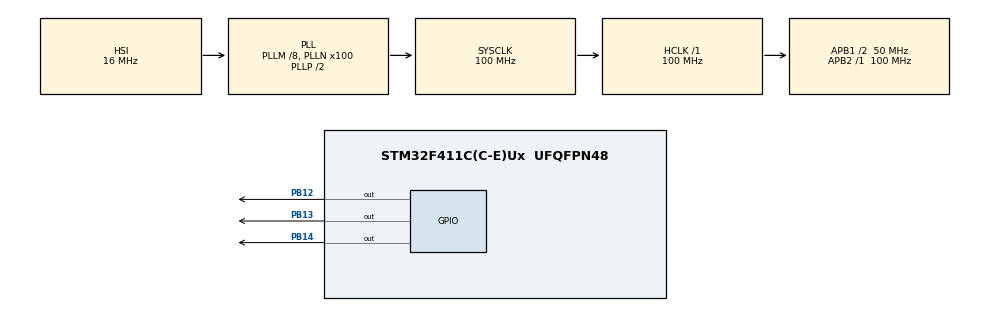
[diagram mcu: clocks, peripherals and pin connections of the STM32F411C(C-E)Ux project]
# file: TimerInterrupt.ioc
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Mcu.Family=STM32F4
Mcu.Name=STM32F411C(C-E)Ux
Mcu.Package=UFQFPN48
NVIC.PriorityGroup=NVIC_PRIORITYGROUP_4
NVIC.TIM2_IRQn=true\:0\:0\:false\:false\:true\:true\:true\:true
NVIC.TIM3_IRQn=true\:0\:0\:false\:false\:true\:true\:true\:true
NVIC.TIM4_IRQn=true\:0\:0\:false\:false\:true\:true\:true\:true
PA13.Mode=Serial_Wire
PA13.Signal=SYS_JTMS-SWDIO
PA14.Mode=Serial_Wire
PA14.Signal=SYS_JTCK-SWCLK
PB12.Signal=GPIO_Output
PB13.Signal=GPIO_Output
PB14.Signal=GPIO_Output
PH0\ -\ OSC_IN.Mode=HSE-External-Oscillator
PH0\ -\ OSC_IN.Signal=RCC_OSC_IN
PH1\ -\ OSC_OUT.Mode=HSE-External-Oscillator
PH1\ -\ OSC_OUT.Signal=RCC_OSC_OUT
ProjectManager.HeapSize=0x200
ProjectManager.StackSize=0x400
ProjectManager.TargetToolchain=STM32CubeIDE
RCC.48MHZClocksFreq_Value=50000000
RCC.AHBFreq_Value=100000000
RCC.APB1CLKDivider=RCC_HCLK_DIV2
RCC.APB1Freq_Value=50000000
RCC.APB1TimFreq_Value=100000000
RCC.APB2Freq_Value=100000000
RCC.APB2TimFreq_Value=100000000
RCC.CortexFreq_Value=100000000
RCC.HCLKFreq_Value=100000000
RCC.HSE_VALUE=25000000
RCC.HSI_VALUE=16000000
RCC.LSE_VALUE=32768
RCC.PLLM=8
RCC.PLLN=100
RCC.SYSCLKFreq_VALUE=100000000
RCC.SYSCLKSource=RCC_SYSCLKSOURCE_PLLCLK
RCC.VCOOutputFreq_Value=200000000
TIM2.Period=2000-1
TIM2.Prescaler=10000-1
TIM3.Period=5000-1
TIM3.Prescaler=10000-1
TIM4.Period=7500-1
TIM4.Prescaler=10000-1
VP_TIM2_VS_ClockSourceINT.Mode=Internal
VP_TIM3_VS_ClockSourceINT.Mode=Internal
VP_TIM4_VS_ClockSourceINT.Mode=Internal
board=custom

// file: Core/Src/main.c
/* USER CODE BEGIN Header */
/**
  ******************************************************************************
  * @file           : main.c
  * @brief          : Interrupción por Timer
  ******************************************************************************
  * Configuración:
  * - TIM2: Interrupción cada 200 ms (5Hz)
  * - TIM3: Interrupción cada 500 ms (2Hz)
  * - TIM4: Interrupción cada 750 ms (1.33Hz)
  ******************************************************************************
  */
/* USER CODE END Header */
#include "main.h"

TIM_HandleTypeDef htim2;
TIM_HandleTypeDef htim3;
TIM_HandleTypeDef htim4;

void SystemClock_Config(void);
static void MX_GPIO_Init(void);
static void MX_TIM2_Init(void);
static void MX_TIM3_Init(void);
static void MX_TIM4_Init(void);

int main(void)
{

  /* MCU Configuration--------------------------------------------------------*/

  /* Reset of all peripherals, Initializes the Flash interface and the Systick. */
  HAL_Init();

  /* Configure the system clock */
  SystemClock_Config();

  /* Initialize all configured peripherals */
  MX_GPIO_Init();
  MX_TIM2_Init();
  MX_TIM3_Init();
  MX_TIM4_Init();
  /* USER CODE BEGIN 2 */

  // Inicialización de timers en modo interrupción
  HAL_TIM_Base_Start_IT(&htim2);  // Inicia TIM2

  HAL_TIM_Base_Start_IT(&htim3);  // Inicia TIM3

  HAL_TIM_Base_Start_IT(&htim4);  // Inicia TIM4

  /* USER CODE END 2 */

  /* Infinite loop */
  while (1)
  {

  }
}

void SystemClock_Config(void)
{
  RCC_OscInitTypeDef RCC_OscInitStruct = {0};
  RCC_ClkInitTypeDef RCC_ClkInitStruct = {0};

  /** Configure the main internal regulator output voltage
  */
  __HAL_RCC_PWR_CLK_ENABLE();
  __HAL_PWR_VOLTAGESCALING_CONFIG(PWR_REGULATOR_VOLTAGE_SCALE1);

  /** Initializes the RCC Oscillators according to the specified parameters
  * in the RCC_OscInitTypeDef structure.
  */
  RCC_OscInitStruct.OscillatorType = RCC_OSCILLATORTYPE_HSI;
  RCC_OscInitStruct.HSIState = RCC_HSI_ON;
  RCC_OscInitStruct.HSICalibrationValue = RCC_HSICALIBRATION_DEFAULT;
  RCC_OscInitStruct.PLL.PLLState = RCC_PLL_ON;
  RCC_OscInitStruct.PLL.PLLSource = RCC_PLLSOURCE_HSI;
  RCC_OscInitStruct.PLL.PLLM = 8;
  RCC_OscInitStruct.PLL.PLLN = 100;
  RCC_OscInitStruct.PLL.PLLP = RCC_PLLP_DIV2;
  RCC_OscInitStruct.PLL.PLLQ = 4;
  if (HAL_RCC_OscConfig(&RCC_OscInitStruct) != HAL_OK)
  {
    Error_Handler();
  }

  /** Initializes the CPU, AHB and APB buses clocks
  */
  RCC_ClkInitStruct.ClockType = RCC_CLOCKTYPE_HCLK|RCC_CLOCKTYPE_SYSCLK
                              |RCC_CLOCKTYPE_PCLK1|RCC_CLOCKTYPE_PCLK2;
  RCC_ClkInitStruct.SYSCLKSource = RCC_SYSCLKSOURCE_PLLCLK;
  RCC_ClkInitStruct.AHBCLKDivider = RCC_SYSCLK_DIV1;
  RCC_ClkInitStruct.APB1CLKDivider = RCC_HCLK_DIV2;
  RCC_ClkInitStruct.APB2CLKDivider = RCC_HCLK_DIV1;

  if (HAL_RCC_ClockConfig(&RCC_ClkInitStruct, FLASH_LATENCY_3) != HAL_OK)
  {
    Error_Handler();
  }
}

static void MX_TIM2_Init(void)
{

  TIM_ClockConfigTypeDef sClockSourceConfig = {0};
  TIM_MasterConfigTypeDef sMasterConfig = {0};

  htim2.Instance = TIM2;
  htim2.Init.Prescaler = 10000-1;
  htim2.Init.CounterMode = TIM_COUNTERMODE_UP;
  htim2.Init.Period = 2000-1;
  htim2.Init.ClockDivision = TIM_CLOCKDIVISION_DIV1;
  htim2.Init.AutoReloadPreload = TIM_AUTORELOAD_PRELOAD_DISABLE;
  if (HAL_TIM_Base_Init(&htim2) != HAL_OK)
  {
    Error_Handler();
  }
  sClockSourceConfig.ClockSource = TIM_CLOCKSOURCE_INTERNAL;
  if (HAL_TIM_ConfigClockSource(&htim2, &sClockSourceConfig) != HAL_OK)
  {
    Error_Handler();
  }
  sMasterConfig.MasterOutputTrigger = TIM_TRGO_RESET;
  sMasterConfig.MasterSlaveMode = TIM_MASTERSLAVEMODE_DISABLE;
  if (HAL_TIMEx_MasterConfigSynchronization(&htim2, &sMasterConfig) != HAL_OK)
  {
    Error_Handler();
  }

}

static void MX_TIM3_Init(void)
{

  TIM_ClockConfigTypeDef sClockSourceConfig = {0};
  TIM_MasterConfigTypeDef sMasterConfig = {0};

  htim3.Instance = TIM3;
  htim3.Init.Prescaler = 10000-1;
  htim3.Init.CounterMode = TIM_COUNTERMODE_UP;
  htim3.Init.Period = 5000-1;
  htim3.Init.ClockDivision = TIM_CLOCKDIVISION_DIV1;
  htim3.Init.AutoReloadPreload = TIM_AUTORELOAD_PRELOAD_DISABLE;
  if (HAL_TIM_Base_Init(&htim3) != HAL_OK)
  {
    Error_Handler();
  }
  sClockSourceConfig.ClockSource = TIM_CLOCKSOURCE_INTERNAL;
  if (HAL_TIM_ConfigClockSource(&htim3, &sClockSourceConfig) != HAL_OK)
  {
    Error_Handler();
  }
  sMasterConfig.MasterOutputTrigger = TIM_TRGO_RESET;
  sMasterConfig.MasterSlaveMode = TIM_MASTERSLAVEMODE_DISABLE;
  if (HAL_TIMEx_MasterConfigSynchronization(&htim3, &sMasterConfig) != HAL_OK)
  {
    Error_Handler();
  }

}

static void MX_TIM4_Init(void)
{

  TIM_ClockConfigTypeDef sClockSourceConfig = {0};
  TIM_MasterConfigTypeDef sMasterConfig = {0};

  htim4.Instance = TIM4;
  htim4.Init.Prescaler = 10000-1;
  htim4.Init.CounterMode = TIM_COUNTERMODE_UP;
  htim4.Init.Period = 7500-1;
  htim4.Init.ClockDivision = TIM_CLOCKDIVISION_DIV1;
  htim4.Init.AutoReloadPreload = TIM_AUTORELOAD_PRELOAD_DISABLE;
  if (HAL_TIM_Base_Init(&htim4) != HAL_OK)
  {
    Error_Handler();
  }
  sClockSourceConfig.ClockSource = TIM_CLOCKSOURCE_INTERNAL;
  if (HAL_TIM_ConfigClockSource(&htim4, &sClockSourceConfig) != HAL_OK)
  {
    Error_Handler();
  }
  sMasterConfig.MasterOutputTrigger = TIM_TRGO_RESET;
  sMasterConfig.MasterSlaveMode = TIM_MASTERSLAVEMODE_DISABLE;
  if (HAL_TIMEx_MasterConfigSynchronization(&htim4, &sMasterConfig) != HAL_OK)
  {
    Error_Handler();
  }

}

static void MX_GPIO_Init(void)
{
  GPIO_InitTypeDef GPIO_InitStruct = {0};

  /* GPIO Ports Clock Enable */
  __HAL_RCC_GPIOH_CLK_ENABLE();
  __HAL_RCC_GPIOB_CLK_ENABLE();
  __HAL_RCC_GPIOA_CLK_ENABLE();

  /*Configure GPIO pin Output Level */
  HAL_GPIO_WritePin(GPIOB, GPIO_PIN_12|GPIO_PIN_13|GPIO_PIN_14, GPIO_PIN_RESET);

  /*Configure GPIO pins : PB12 PB13 PB14 */
  GPIO_InitStruct.Pin = GPIO_PIN_12|GPIO_PIN_13|GPIO_PIN_14;
  GPIO_InitStruct.Mode = GPIO_MODE_OUTPUT_PP;
  GPIO_InitStruct.Pull = GPIO_NOPULL;
  GPIO_InitStruct.Speed = GPIO_SPEED_FREQ_LOW;
  HAL_GPIO_Init(GPIOB, &GPIO_InitStruct);

}

/* USER CODE BEGIN 4 */

/**
  * @brief  Callback ejecutado cuando un Timer genera una interrupción.
  * @param  htim: puntero al manejador del Timer que generó la interrupción.
  * @retval None
  */
void HAL_TIM_PeriodElapsedCallback(TIM_HandleTypeDef *htim)
{
  // Verifica qué Timer generó la interrupción y alterna el estado del pin correspondiente

  // Alterna el pin PB12 cuando TIM2 genera la interrupción
  if(htim -> Instance == TIM2)
	{
		HAL_GPIO_TogglePin(GPIOB, GPIO_PIN_12);
	}

  // Alterna el pin PB13 cuando TIM3 genera la interrupción
	if(htim -> Instance == TIM3)
	{
		HAL_GPIO_TogglePin(GPIOB, GPIO_PIN_13);
	}

  // Alterna el pin PB14 cuando TIM4 genera la interrupción
	if(htim -> Instance == TIM4)
	{
		HAL_GPIO_TogglePin(GPIOB, GPIO_PIN_14);
	}
}
/* USER CODE END 4 */

void Error_Handler(void)
{
  __disable_irq();
  while (1)
  {
  }
}
